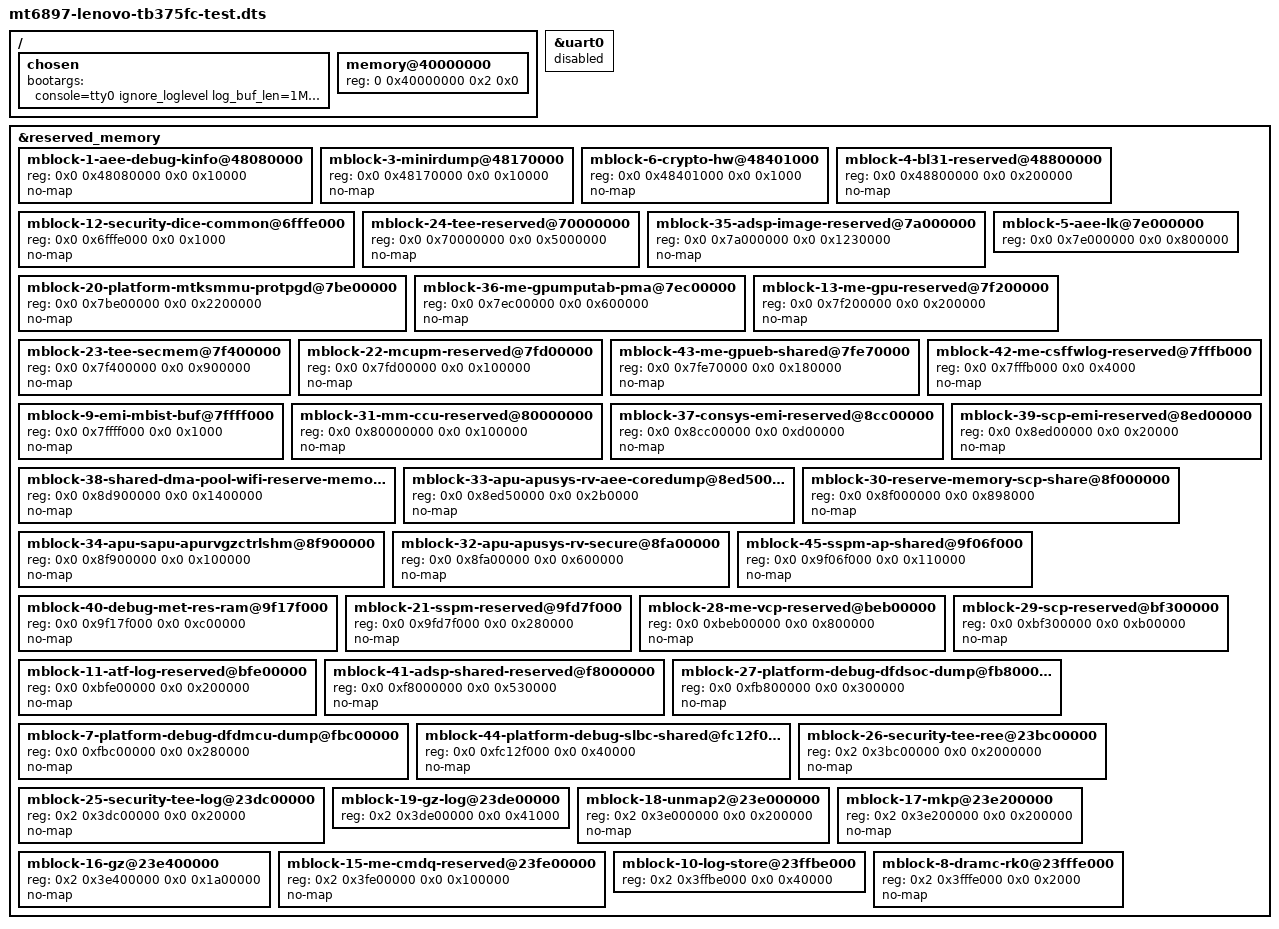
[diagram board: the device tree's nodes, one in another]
// SPDX-License-Identifier: (GPL-2.0-only OR BSD-2-Clause)
// 시험용: 커널에 넣는 트리. gen_dts.py가 기기의 살아 있는 트리에서 만들었다.
#include "mt6897-lenovo-tb375fc.dts"
#include "test-stage.dtsi"

/ {
	chosen {
		/delete-property/ stdout-path;
		bootargs = "console=tty0 ignore_loglevel log_buf_len=1M root=PARTLABEL=buntos rootfstype=btrfs rw systemd.firstboot=no buntos.usbdebug=1 buntos.wait=10 buntos.telnet=1 buntos.autoreboot=30 buntos.dump=1 panic=30 clk_ignore_unused pd_ignore_unused regulator_ignore_unused arm64.nomte";
	};

	memory@40000000 {
		reg = <0 0x40000000 0x2 0x0>;
	};
};

&uart0 {
	status = "disabled";
};

&reserved_memory {
	mblock-1-aee-debug-kinfo@48080000 {
		reg = <0x0 0x48080000 0x0 0x10000>;
		no-map;
	};
	mblock-3-minirdump@48170000 {
		reg = <0x0 0x48170000 0x0 0x10000>;
		no-map;
	};
	mblock-6-crypto-hw@48401000 {
		reg = <0x0 0x48401000 0x0 0x1000>;
		no-map;
	};
	mblock-4-bl31-reserved@48800000 {
		reg = <0x0 0x48800000 0x0 0x200000>;
		no-map;
	};
	mblock-12-security-dice-common@6fffe000 {
		reg = <0x0 0x6fffe000 0x0 0x1000>;
		no-map;
	};
	mblock-24-tee-reserved@70000000 {
		reg = <0x0 0x70000000 0x0 0x5000000>;
		no-map;
	};
	mblock-35-adsp-image-reserved@7a000000 {
		reg = <0x0 0x7a000000 0x0 0x1230000>;
		no-map;
	};
	mblock-20-platform-mtksmmu-protpgd@7be00000 {
		reg = <0x0 0x7be00000 0x0 0x2200000>;
		no-map;
	};
	mblock-5-aee-lk@7e000000 {
		reg = <0x0 0x7e000000 0x0 0x800000>;
	};
	mblock-36-me-gpumputab-pma@7ec00000 {
		reg = <0x0 0x7ec00000 0x0 0x600000>;
		no-map;
	};
	mblock-13-me-gpu-reserved@7f200000 {
		reg = <0x0 0x7f200000 0x0 0x200000>;
		no-map;
	};
	mblock-23-tee-secmem@7f400000 {
		reg = <0x0 0x7f400000 0x0 0x900000>;
		no-map;
	};
	mblock-22-mcupm-reserved@7fd00000 {
		reg = <0x0 0x7fd00000 0x0 0x100000>;
		no-map;
	};
	mblock-43-me-gpueb-shared@7fe70000 {
		reg = <0x0 0x7fe70000 0x0 0x180000>;
		no-map;
	};
	mblock-42-me-csffwlog-reserved@7fffb000 {
		reg = <0x0 0x7fffb000 0x0 0x4000>;
		no-map;
	};
	mblock-9-emi-mbist-buf@7ffff000 {
		reg = <0x0 0x7ffff000 0x0 0x1000>;
		no-map;
	};
	mblock-31-mm-ccu-reserved@80000000 {
		reg = <0x0 0x80000000 0x0 0x100000>;
		no-map;
	};
	mblock-37-consys-emi-reserved@8cc00000 {
		reg = <0x0 0x8cc00000 0x0 0xd00000>;
		no-map;
	};
	mblock-38-shared-dma-pool-wifi-reserve-memory-dma@8d900000 {
		reg = <0x0 0x8d900000 0x0 0x1400000>;
		no-map;
	};
	mblock-39-scp-emi-reserved@8ed00000 {
		reg = <0x0 0x8ed00000 0x0 0x20000>;
		no-map;
	};
	mblock-33-apu-apusys-rv-aee-coredump@8ed50000 {
		reg = <0x0 0x8ed50000 0x0 0x2b0000>;
		no-map;
	};
	mblock-30-reserve-memory-scp-share@8f000000 {
		reg = <0x0 0x8f000000 0x0 0x898000>;
		no-map;
	};
	mblock-34-apu-sapu-apurvgzctrlshm@8f900000 {
		reg = <0x0 0x8f900000 0x0 0x100000>;
		no-map;
	};
	mblock-32-apu-apusys-rv-secure@8fa00000 {
		reg = <0x0 0x8fa00000 0x0 0x600000>;
		no-map;
	};
	mblock-45-sspm-ap-shared@9f06f000 {
		reg = <0x0 0x9f06f000 0x0 0x110000>;
		no-map;
	};
	mblock-40-debug-met-res-ram@9f17f000 {
		reg = <0x0 0x9f17f000 0x0 0xc00000>;
		no-map;
	};
	mblock-21-sspm-reserved@9fd7f000 {
		reg = <0x0 0x9fd7f000 0x0 0x280000>;
		no-map;
	};
	mblock-28-me-vcp-reserved@beb00000 {
		reg = <0x0 0xbeb00000 0x0 0x800000>;
		no-map;
	};
	mblock-29-scp-reserved@bf300000 {
		reg = <0x0 0xbf300000 0x0 0xb00000>;
		no-map;
	};
	mblock-11-atf-log-reserved@bfe00000 {
		reg = <0x0 0xbfe00000 0x0 0x200000>;
		no-map;
	};
	mblock-41-adsp-shared-reserved@f8000000 {
		reg = <0x0 0xf8000000 0x0 0x530000>;
		no-map;
	};
	mblock-27-platform-debug-dfdsoc-dump@fb800000 {
		reg = <0x0 0xfb800000 0x0 0x300000>;
		no-map;
	};
	mblock-7-platform-debug-dfdmcu-dump@fbc00000 {
		reg = <0x0 0xfbc00000 0x0 0x280000>;
		no-map;
	};
	mblock-44-platform-debug-slbc-shared@fc12f000 {
		reg = <0x0 0xfc12f000 0x0 0x40000>;
		no-map;
	};
	mblock-26-security-tee-ree@23bc00000 {
		reg = <0x2 0x3bc00000 0x0 0x2000000>;
		no-map;
	};
	mblock-25-security-tee-log@23dc00000 {
		reg = <0x2 0x3dc00000 0x0 0x20000>;
		no-map;
	};
	mblock-19-gz-log@23de00000 {
		reg = <0x2 0x3de00000 0x0 0x41000>;
	};
	mblock-18-unmap2@23e000000 {
		reg = <0x2 0x3e000000 0x0 0x200000>;
		no-map;
	};
	mblock-17-mkp@23e200000 {
		reg = <0x2 0x3e200000 0x0 0x200000>;
		no-map;
	};
	mblock-16-gz@23e400000 {
		reg = <0x2 0x3e400000 0x0 0x1a00000>;
		no-map;
	};
	mblock-15-me-cmdq-reserved@23fe00000 {
		reg = <0x2 0x3fe00000 0x0 0x100000>;
		no-map;
	};
	mblock-10-log-store@23ffbe000 {
		reg = <0x2 0x3ffbe000 0x0 0x40000>;
	};
	mblock-8-dramc-rk0@23fffe000 {
		reg = <0x2 0x3fffe000 0x0 0x2000>;
		no-map;
	};
};
